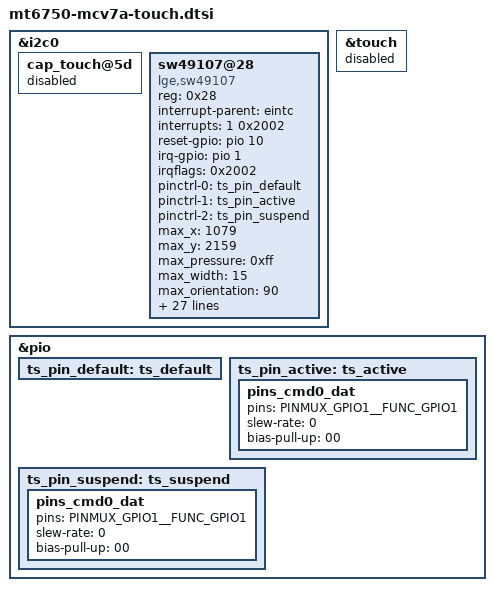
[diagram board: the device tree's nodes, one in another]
/*
 * LG Electronics CV7 touch device tree source
 *
 * Copyright (c) 2017 LG Electronics Co., Ltd.
 *              http://www.lge.com
 *
 */

&i2c0 {

	cap_touch@5d {
		status = "disabled";
	};

	sw49107@28 {
		compatible = "lge,sw49107";
		status = "ok";

		reg = <0x28>;

		/* GPIOs */
		interrupt-parent = <&eintc>;
		interrupts = <1 0x2002>;

		/* IRQF_ONESHOT		0x00002000 */
		/* IRQF_TRIGGER_FALLING		0x00000002 */
		/* IRQF_NO_SUSPEND		0x00004000 */

		reset-gpio = <&pio 10 0x0>;
		irq-gpio = <&pio 1 0x2002>;
		irqflags = <0x2002>;

		pinctrl-names = "default", "touch_pin_active", "touch_pin_sleep";	/* Touch GPIO pin name setting */
		pinctrl-0 = <&ts_pin_default>;
		pinctrl-1 = <&ts_pin_active>;		/* Touch GPIO pin active setting */
		pinctrl-2 = <&ts_pin_suspend>;		/* Touch GPIO pin suspend setting */

		//vdd-gpio = <&eintc 3 0x0>;  /* ???? 3 : ph2 3.3v/l5 mipi 1.2v */
		//vio-gpio = <&eintc 63 0x0>; /* ???? 63 : 1.8v io*/

		/* Caps */
		max_x = <1079>;
		max_y = <2159>;
		max_pressure = <0xff>;
                max_width = <15>;
		max_orientation = <90>;
		max_id = <10>;

		/* role */
		hw_reset_delay = <210>;
		sw_reset_delay = <90>;
		use_lpwg = <1>;
		use_lpwg_test = <1>;
		hide_coordinate = <1>;

		/* firmware */
		use_fw_upgrade = <1>;
                use_firmware = <0>;

		fw_image = "touch/cv7a/lgsic/L0W62CV7_V1_03.img", "touch/cv7a/lgsic/T0W62CV7_V0_08.img";
		panel_spec = "touch/cv7a/lgsic/cv7a_limit.txt", "touch/cv7a/lgsic/cv7a_tovis_limit.txt";
		panel_spec_mfts_folder = "touch/cv7a/lgsic/cv7a_limit_mfts.txt", "touch/cv7a/lgsic/cv7a_tovis_limit_mfts.txt";

		/* Performance Test */
		use_perf_test = <1>;
		test_delay = <8>;
		test_pressure = <50>;
		test_width = <100>;
		click_test_x = <135>;
		click_test_y = <526>;
		v_drag_test_x = <108>;
		v_drag_test_start_y = <1388>;
		v_drag_test_end_y = <771>;
		h_drag_test_start_x = <848>;
		h_drag_test_end_x = <231>;
		h_drag_test_y = <1512>;
	};

};

&touch {
	status = "disabled";
};

/* touch gpio start */
&pio {
	ts_pin_default: ts_default {
	};

	ts_pin_active: ts_active {
		pins_cmd0_dat {
			pins = <PINMUX_GPIO1__FUNC_GPIO1>;
			slew-rate = <0>;
			bias-pull-up = <00>;
		};
	};

	ts_pin_suspend: ts_suspend {
		pins_cmd0_dat {
			pins = <PINMUX_GPIO1__FUNC_GPIO1>;
			slew-rate = <0>;
			bias-pull-up = <00>;
		};
	};
};
/* touch gpio end */
